# PIC32CM1216MC00032 device description
Architecture: CORTEX-M0PLUS; Family: PIC32CMMC; Series: PIC32CMMC00
Registers are 32-bit, read-write, reset 0x0 unless marked. A register's access mark holds for its fields unless they carry their own. Offsets are from the block's base; [hi:lo] are bit positions; 'fields as' and 'values as' point back to an identical list.

## LOCKBIT_FUSES — Non-Volatile Fuses
0x00 LOCKBIT_WORD_0 ro reset not defined — LOCKBIT Page Word 0
  [29:24] NVMCTRL_CEHL — CEHL Bits

## OTP1_FUSES — Non-Volatile Fuses
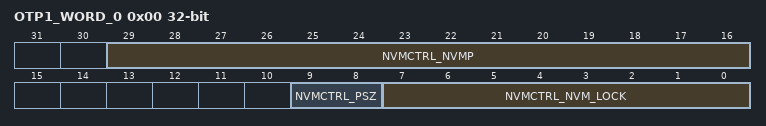
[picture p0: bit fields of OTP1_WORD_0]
0x00 OTP1_WORD_0 ro reset not defined — OTP1 Page Word 0
  [29:16] NVMCTRL_NVMP — Number of NVM Pages
  [9:8] NVMCTRL_PSZ — NVM Page Size
  [7:0] NVMCTRL_NVM_LOCK — NVM Lock
0x04 OTP1_WORD_1 ro reset not defined — OTP1 Page Word 1
  [7:0] NVMCTRL_DATAFLASHP — Number of Data Flash Pages

## OTP2_FUSES — Non-Volatile Fuses
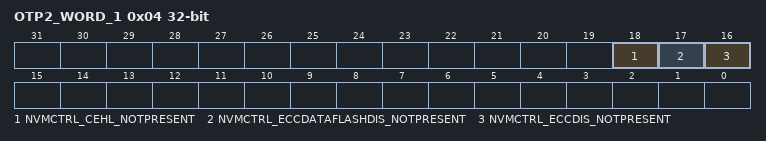
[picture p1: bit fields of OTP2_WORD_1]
0x04 OTP2_WORD_1 ro reset not defined — OTP2 Page Word 1
  [18] NVMCTRL_CEHL_NOTPRESENT — Allows the CEHL bit to be able to be used by the user to Chip Erase Hard Lock or disabled and no Chip Erase Hard lock allowed.
  [17] NVMCTRL_ECCDATAFLASHDIS_NOTPRESENT — Allows the ECC Data Flash disable bit (ECCCTRL.ECCDFDIS) to become not available for the user with a device fuse.
  [16] NVMCTRL_ECCDIS_NOTPRESENT — Allows the ECC disable bit (ECCCTRL.ECCDIS) to become not available for the user with a device fuse.

## OTP3_FUSES — Non-Volatile Fuses
0x04 OTP3_WORD_1 ro reset not defined — OTP3 Page Word 1
  [31] NVMCTRL_DUMMY2 — Dummy for OTP3 entry

## OTP4_FUSES — Non-Volatile Fuses
0x04 OTP4_WORD_1 ro reset not defined — OTP4 Page Word 1
  [31] NVMCTRL_DUMMY — Dummy for OTP4 entry

## OTP5_FUSES — Non-Volatile Fuses
Instances: OTP5_FUSES 0x00806020 in fuses
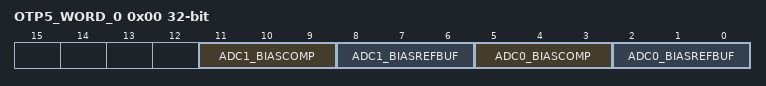
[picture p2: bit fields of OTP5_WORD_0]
0x00 OTP5_WORD_0 ro reset not defined — OTP5 Page Word 0
  [11:9] ADC1_BIASCOMP — ADC Comparator Scaling
  [8:6] ADC1_BIASREFBUF — ADC Bias Reference Buffer Scaling
  [5:3] ADC0_BIASCOMP — ADC Comparator Scaling
  [2:0] ADC0_BIASREFBUF — ADC Bias Reference Buffer Scaling

## TEMP_LOG_FUSES — Non-Volatile Fuses
Instances: TEMP_LOG_FUSES 0x00806030 in fuses
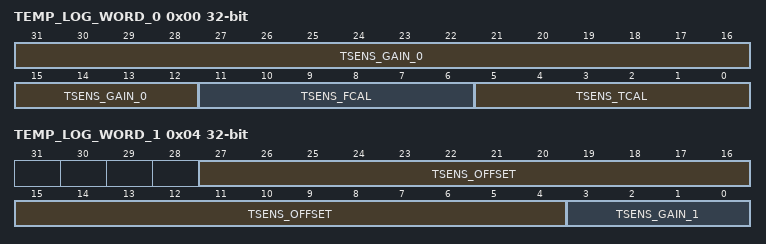
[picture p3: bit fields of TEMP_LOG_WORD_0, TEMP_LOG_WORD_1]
0x00 TEMP_LOG_WORD_0 ro reset not defined — TEMP_LOG Page Word 0
  [31:12] TSENS_GAIN_0 — Gain Calibration bits 19:0
  [11:6] TSENS_FCAL — Frequency Calibration
  [5:0] TSENS_TCAL — Temperature Calibration
0x04 TEMP_LOG_WORD_1 ro reset not defined — TEMP_LOG Page Word 1
  [27:4] TSENS_OFFSET — Offse Calibration
  [3:0] TSENS_GAIN_1 — Gain Calibration bits 23:20

## USER_FUSES — Non-Volatile Fuses
Instances: USER_FUSES 0x00804000 in fuses
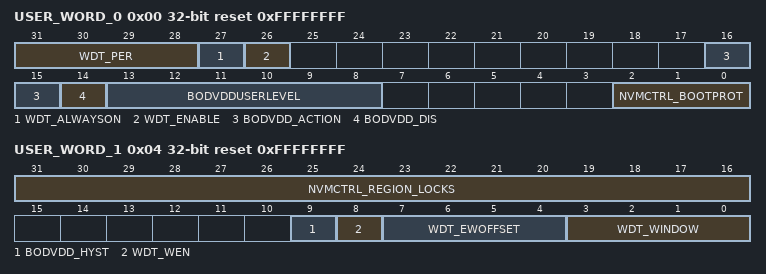
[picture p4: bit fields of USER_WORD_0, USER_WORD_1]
0x00 USER_WORD_0 reset 0xFFFFFFFF — USER Page Word 0
  [31:28] WDT_PER — WDT Period
    0=CYC8 (8 clock cycles); 1=CYC16 (16 clock cycles); 2=CYC32 (32 clock cycles); 3=CYC64 (64 clock cycles); 4=CYC128 (128 clock cycles); 5=CYC256 (256 clock cycles); 6=CYC512 (512 clock cycles); 7=CYC1024 (1024 clock cycles); 8=CYC2048 (2048 clock cycles); 9=CYC4096 (4096 clock cycles); 10=CYC8192 (8192 clock cycles); 11=CYC16384 (16384 clock cycles)
  [27] WDT_ALWAYSON
    0=DISABLED (WDT is enabled and disabled through ENABLE bit); 1=ENABLED (WDT is enabled and can only be disabled by a power-on reset)
  [26] WDT_ENABLE
    0=DISABLED (WDT is disabled on power on); 1=ENABLED (WDT is enabled on power on)
  [16:15] BODVDD_ACTION
    0=NONE (No action); 1=RESET (The BODVDD generates a reset); 2=INT (The BODVDD generates an interrupt)
  [14] BODVDD_DIS — BODVDD Disable
    0=ENABLED (BODVDD is enabled on power on); 1=DISABLED (BODVDD is disabled on power on)
  [13:8] BODVDDUSERLEVEL
  [2:0] NVMCTRL_BOOTPROT — Bootloader Size
    7=SIZE_0BYTES (0 Bytes); 6=SIZE_512BYTES (512 Bytes); 5=SIZE_1024BYTES (1024 Bytes); 4=SIZE_2048BYTES (2048 Bytes); 3=SIZE_4096BYTES (4096 Bytes); 2=SIZE_8192BYTES (8192 Bytes); 1=SIZE_16384BYTES (16384 Bytes); 0=SIZE_32768BYTES (32768 Bytes)
0x04 USER_WORD_1 reset 0xFFFFFFFF — USER Page Word 1
  [31:16] NVMCTRL_REGION_LOCKS — NVM Region lock bits
  [9] BODVDD_HYST — BODVDD Hysterisis
    0=DISABLED (No Hysteresis); 1=ENABLED (Hysteresis Enabled)
  [8] WDT_WEN — WDT Window Mode Enable
    0=DISABLED (WDT is disabled); 1=ENABLED (WDT is enabled)
  [7:4] WDT_EWOFFSET — WDT Early Warning Offset
    values as USER_WORD_0.WDT_PER
  [3:0] WDT_WINDOW
    values as USER_WORD_0.WDT_PER

## Notices in the file
Copyright (c) 2019 Microchip Technology Inc.
SPDX-License-Identifier: Apache-2.0
Licensed under the Apache License, Version 2.0 (the "License");
you may not use this file except in compliance with the License.
You may obtain a copy of the License at
http://www.apache.org/licenses/LICENSE-2.0
Unless required by applicable law or agreed to in writing, software
distributed under the License is distributed on an "AS IS" BASIS,
WITHOUT WARRANTIES OR CONDITIONS OF ANY KIND, either express or implied.
See the License for the specific language governing permissions and
limitations under the License.
